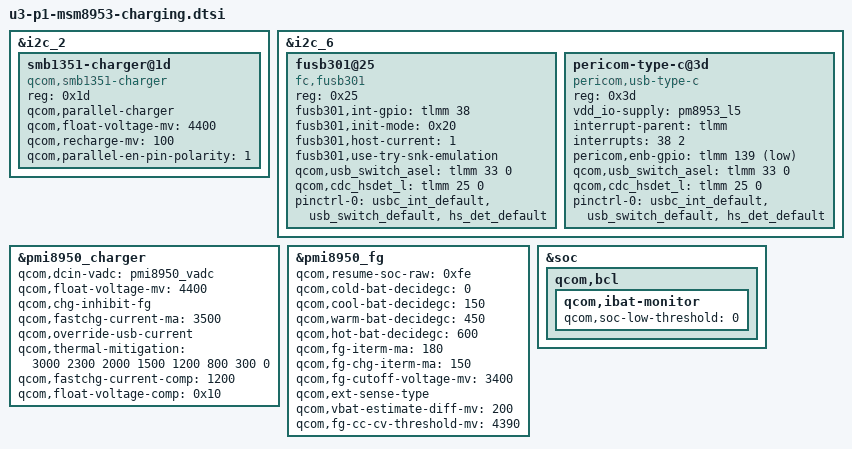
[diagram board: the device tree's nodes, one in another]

&i2c_2 {
	/* DSI_TO_HDMI I2C configuration */
	smb1351-charger@1d {
		compatible = "qcom,smb1351-charger";
		reg = <0x1d>;
		qcom,parallel-charger;
		qcom,float-voltage-mv = <4400>;
		qcom,recharge-mv = <100>;
		qcom,parallel-en-pin-polarity = <1>;
	};
};

&i2c_6 {
	fusb301@25 {
		compatible = "fc,fusb301";
		reg = <0x25>;
		fusb301,int-gpio = <&tlmm 38 0>;
		fusb301,init-mode = /bits/ 8 <0x20>;
		fusb301,host-current = /bits/ 8 <1>;
		fusb301,use-try-snk-emulation;
		qcom,usb_switch_asel = <&tlmm 33 0>;
		qcom,cdc_hsdet_l = <&tlmm 25 0>;
		pinctrl-names = "default";
		pinctrl-0 = <&usbc_int_default &usb_switch_default &hs_det_default>;
	};
	pericom-type-c@3d {
		compatible = "pericom,usb-type-c";
		reg = <0x3d>;
		vdd_io-supply = <&pm8953_l5>;
		interrupt-parent = <&tlmm>;
		interrupts = <38 2>;  /* TLMM 38, TRIGGER_FALLING */
		pericom,enb-gpio = <&tlmm 139 0x1>;	/* active low */
		qcom,usb_switch_asel = <&tlmm 33 0>;
		qcom,cdc_hsdet_l = <&tlmm 25 0>;
		pinctrl-names = "default";
		pinctrl-0 = <&usbc_int_default &usb_switch_default &hs_det_default>;
	};
};


&pmi8950_charger {
	qcom,dcin-vadc = <&pmi8950_vadc>;
	qcom,float-voltage-mv = <4400>;
	qcom,chg-inhibit-fg;
	qcom,fastchg-current-ma = <3500>;
	qcom,override-usb-current;
	qcom,thermal-mitigation = <3000 2300 2000 1500 1200 800 300 0>;
	qcom,fastchg-current-comp = <1200>;
	qcom,float-voltage-comp = <0x10>;
};

&pmi8950_fg {
	qcom,resume-soc-raw = <0xfe>;
	qcom,cold-bat-decidegc = <0>;
	qcom,cool-bat-decidegc = <150>;
	qcom,warm-bat-decidegc = <450>;
	qcom,hot-bat-decidegc = <600>;
	qcom,fg-iterm-ma = <180>;
	qcom,fg-chg-iterm-ma = <150>;
	qcom,fg-cutoff-voltage-mv = <3400>;
	/* use external rsense for parallel charging */
	qcom,ext-sense-type;
	qcom,vbat-estimate-diff-mv = <200>;
	qcom,fg-cc-cv-threshold-mv = <4390>;
};

&soc {
qcom,bcl {
		qcom,ibat-monitor {
		qcom,soc-low-threshold = <0>;
		};
	};
};

